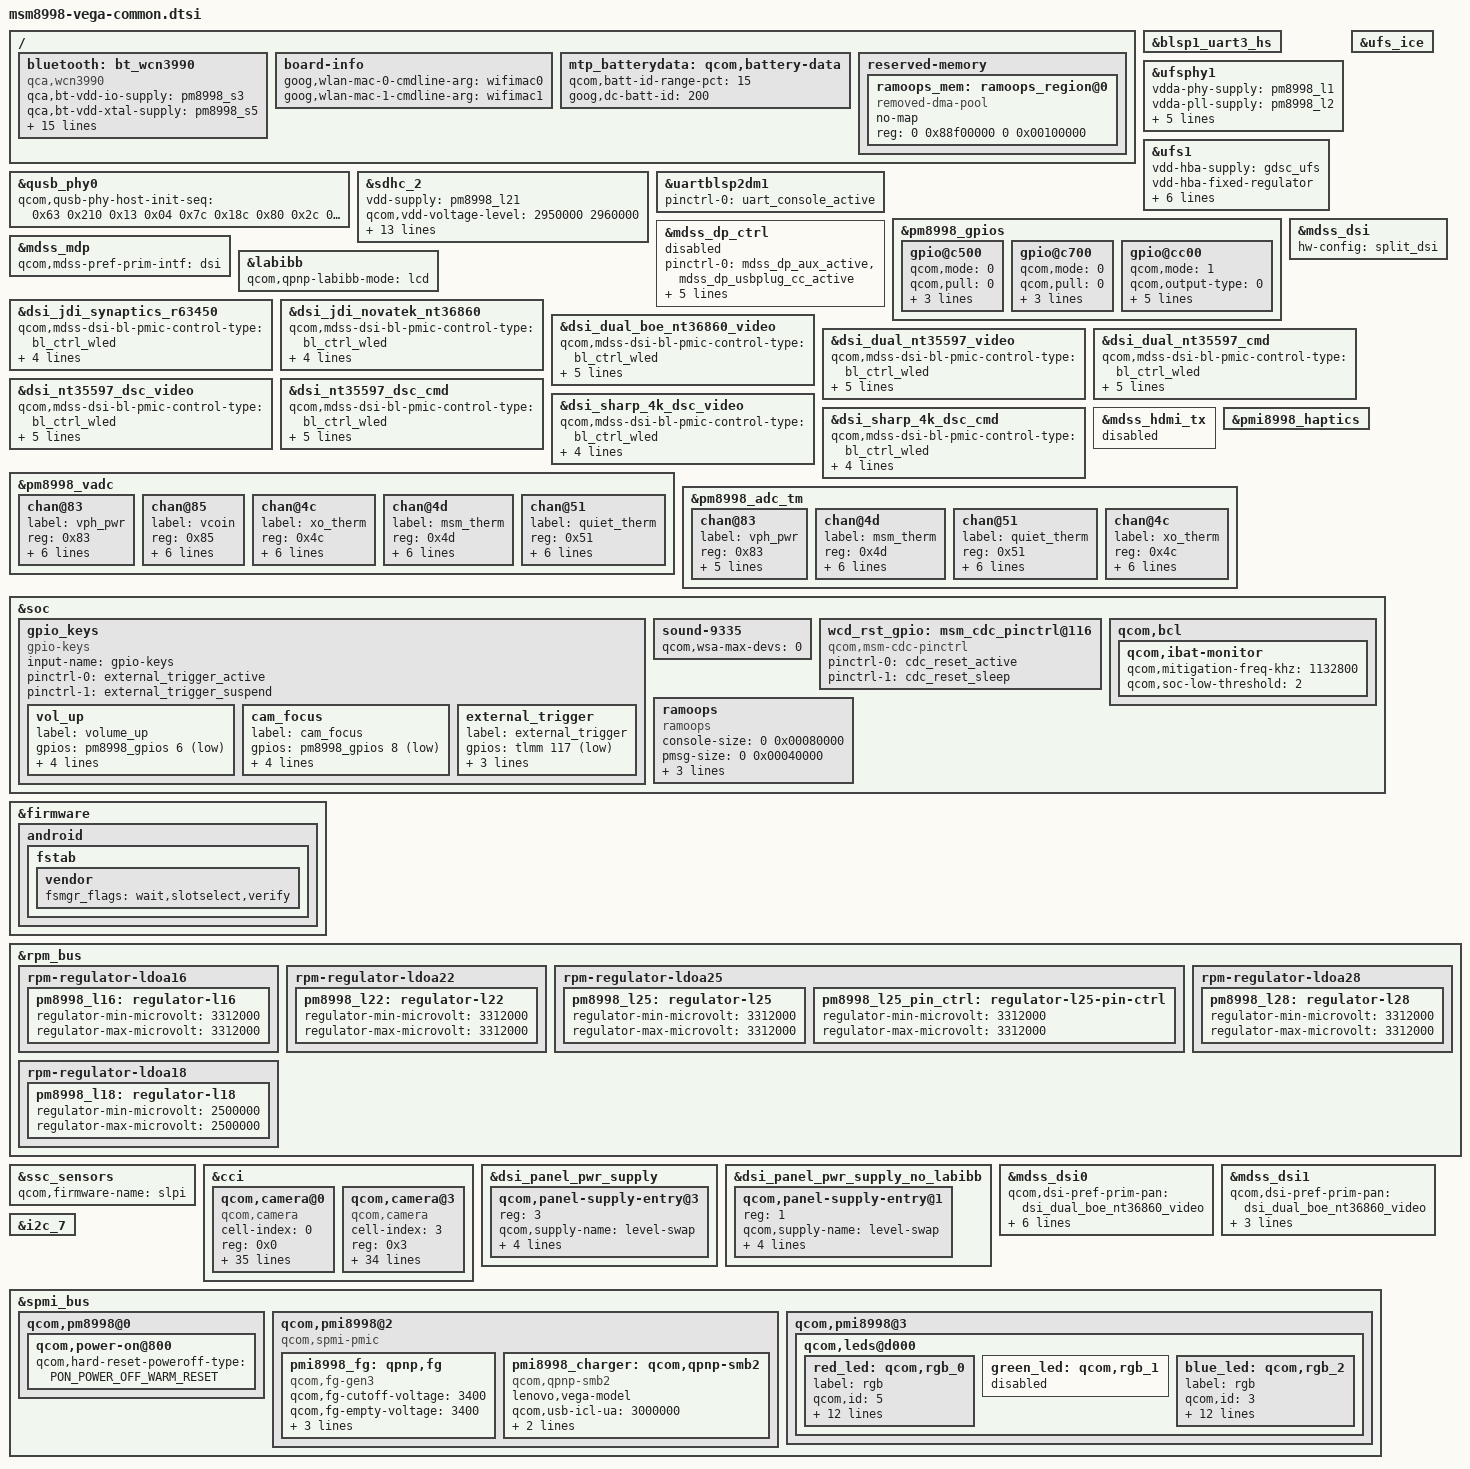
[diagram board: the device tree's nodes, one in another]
/* Copyright (c) 2016, The Linux Foundation. All rights reserved.
 *
 * This program is free software; you can redistribute it and/or modify
 * it under the terms of the GNU General Public License version 2 and
 * only version 2 as published by the Free Software Foundation.
 *
 * This program is distributed in the hope that it will be useful,
 * but WITHOUT ANY WARRANTY; without even the implied warranty of
 * MERCHANTABILITY or FITNESS FOR A PARTICULAR PURPOSE.  See the
 * GNU General Public License for more details.
 */

#include "../qcom/apq8098-v2.1.dtsi"
#include "../qcom/msm8998-camera-sensor-cdp.dtsi"
#include "../qcom/msm8998-mdss-panels.dtsi"

#include <dt-bindings/gpio/gpio.h>
#include <dt-bindings/input/input.h>

#include "../qcom/dsi-panel-jdi-synaptics-r63450.dtsi"
#include "../qcom/dsi-panel-jdi-novatek-nt36860.dtsi"
#include "dsi-panel-boe-nt36860-dualmipi-video.dtsi"
#include "msm8998-vega-pinctrl.dtsi"

/ {
	bluetooth: bt_wcn3990 {
		compatible = "qca,wcn3990";
		qca,bt-vdd-io-supply = <&pm8998_s3>;
		qca,bt-vdd-xtal-supply = <&pm8998_s5>;
		qca,bt-vdd-core-supply = <&pm8998_l7_pin_ctrl>;
		qca,bt-vdd-pa-supply = <&pm8998_l17_pin_ctrl>;
		qca,bt-vdd-ldo-supply = <&pm8998_l25_pin_ctrl>;
		qca,bt-chip-pwd-supply = <&pmi8998_bob_pin1>;

		qca,bt-vdd-io-voltage-level = <1352000 1352000>;
		qca,bt-vdd-xtal-voltage-level = <2040000 2040000>;
		qca,bt-vdd-core-voltage-level = <1800000 1800000>;
		qca,bt-vdd-pa-voltage-level = <1304000 1304000>;
		qca,bt-vdd-ldo-voltage-level = <3312000 3312000>;
		qca,bt-chip-pwd-voltage-level = <3600000 3600000>;

		qca,bt-vdd-io-current-level = <1>; /* LPM/PFM */
		qca,bt-vdd-xtal-current-level = <1>; /* LPM/PFM */
		qca,bt-vdd-core-current-level = <1>; /* LPM/PFM */
		qca,bt-vdd-pa-current-level = <1>; /* LPM/PFM */
		qca,bt-vdd-ldo-current-level = <1>; /* LPM/PFM */
	};

	board-info {
		goog,wlan-mac-0-cmdline-arg = "wifimac0";
		goog,wlan-mac-1-cmdline-arg = "wifimac1";
	};
};

&qusb_phy0 {
	qcom,qusb-phy-host-init-seq =
		/* value reg_offsets> */
		<0x63 0x210
		0x13 0x04
		0x7c 0x18c
		0x80 0x2c
		0x0a 0x184
		0x8c 0x21c
		0x05 0x23c
		0x03 0x240
		0xff 0x218
		0x62 0x210>;
};

&blsp1_uart3_hs {
	status = "ok";
};

&ufsphy1 {
	vdda-phy-supply = <&pm8998_l1>;
	vdda-pll-supply = <&pm8998_l2>;
	vddp-ref-clk-supply = <&pm8998_l26>;
	vdda-phy-max-microamp = <51400>;
	vdda-pll-max-microamp = <14600>;
	vddp-ref-clk-max-microamp = <100>;
	vddp-ref-clk-always-on;
	status = "ok";
};

&ufs1 {
	vdd-hba-supply = <&gdsc_ufs>;
	vdd-hba-fixed-regulator;
	vcc-supply = <&pm8998_l20>;
	vccq-supply = <&pm8998_l26>;
	vccq2-supply = <&pm8998_s4>;
	vcc-max-microamp = <750000>;
	vccq-max-microamp = <560000>;
	vccq2-max-microamp = <750000>;
	status = "ok";
};

&ufs_ice {
	status = "ok";
};

&sdhc_2 {
	vdd-supply = <&pm8998_l21>;
	qcom,vdd-voltage-level = <2950000 2960000>;
	qcom,vdd-current-level = <200 800000>;

	vdd-io-supply = <&pm8998_l13>;
	qcom,vdd-io-voltage-level = <1808000 2960000>;
	qcom,vdd-io-current-level = <200 22000>;

	pinctrl-names = "active", "sleep";
	pinctrl-0 = <&sdc2_clk_on  &sdc2_cmd_on &sdc2_data_on &sdc2_cd_on>;
	pinctrl-1 = <&sdc2_clk_off &sdc2_cmd_off &sdc2_data_off &sdc2_cd_off>;

	qcom,clk-rates = <400000 20000000 25000000
	                        50000000 100000000 200000000>;
	qcom,bus-speed-mode = "SDR12", "SDR25", "SDR50", "DDR50", "SDR104";

	cd-gpios = <&tlmm 95 0x1>;

	status = "ok";
};

&uartblsp2dm1 {
	status = "ok";
	pinctrl-names = "default";
	pinctrl-0 = <&uart_console_active>;
};

&pm8998_gpios {
	/* GPIO 6 for Vol+ Key */
	gpio@c500 {
		status = "okay";
		qcom,mode = <0>;
		qcom,pull = <0>;
		qcom,vin-sel = <0>;
		qcom,src-sel = <0>;
		qcom,out-strength = <1>;
	};

	/* GPIO 8 for Focus Key */
	gpio@c700 {
		status = "okay";
		qcom,mode = <0>;
		qcom,pull = <0>;
		qcom,vin-sel = <0>;
		qcom,src-sel = <0>;
		qcom,out-strength = <1>;
	};

	gpio@cc00 { /* GPIO 13 */
		qcom,mode = <1>;
		qcom,output-type = <0>;
		qcom,pull = <5>;
		qcom,vin-sel = <0>;
		qcom,out-strength = <1>;
		qcom,src-sel = <3>;
		qcom,master-en = <1>;
		status = "okay";
	};
};

&mdss_dp_ctrl {
	status = "disabled";
	pinctrl-names = "mdss_dp_active", "mdss_dp_sleep";
	pinctrl-0 = <&mdss_dp_aux_active &mdss_dp_usbplug_cc_active>;
	pinctrl-1 = <&mdss_dp_aux_suspend &mdss_dp_usbplug_cc_suspend>;
	qcom,aux-en-gpio = <&tlmm 77 0>;
	qcom,aux-sel-gpio = <&tlmm 78 0>;
	qcom,usbplug-cc-gpio = <&tlmm 38 0>;
};

&mdss_mdp {
	qcom,mdss-pref-prim-intf = "dsi";
};

&mdss_dsi {
	hw-config = "split_dsi";
};


&labibb {
	status = "ok";
	qcom,qpnp-labibb-mode = "lcd";
};

&dsi_jdi_synaptics_r63450 {
	qcom,mdss-dsi-bl-pmic-control-type = "bl_ctrl_wled";
	qcom,mdss-dsi-bl-min-level = <1>;
	qcom,mdss-dsi-bl-max-level = <2400>;
	qcom,panel-supply-entries = <&dsi_panel_pwr_supply>;
};

&dsi_jdi_novatek_nt36860 {
	qcom,mdss-dsi-bl-pmic-control-type = "bl_ctrl_wled";
	qcom,mdss-dsi-bl-min-level = <1>;
	qcom,mdss-dsi-bl-max-level = <2400>;
	qcom,panel-supply-entries = <&dsi_panel_pwr_supply>;
};

&dsi_dual_boe_nt36860_video {
	qcom,mdss-dsi-bl-pmic-control-type = "bl_ctrl_wled";
	qcom,mdss-dsi-bl-min-level = <1>;
	qcom,mdss-dsi-bl-max-level = <4095>;
	qcom,mdss-dsi-mode-sel-gpio-state = "dual_port";
	qcom,panel-supply-entries = <&dsi_panel_pwr_supply>;
};

&dsi_dual_nt35597_video {
	qcom,mdss-dsi-bl-pmic-control-type = "bl_ctrl_wled";
	qcom,mdss-dsi-bl-min-level = <1>;
	qcom,mdss-dsi-bl-max-level = <4095>;
	qcom,mdss-dsi-mode-sel-gpio-state = "dual_port";
	qcom,panel-supply-entries = <&dsi_panel_pwr_supply>;
};

&dsi_dual_nt35597_cmd {
	qcom,mdss-dsi-bl-pmic-control-type = "bl_ctrl_wled";
	qcom,mdss-dsi-bl-min-level = <1>;
	qcom,mdss-dsi-bl-max-level = <4095>;
	qcom,mdss-dsi-mode-sel-gpio-state = "dual_port";
	qcom,panel-supply-entries = <&dsi_panel_pwr_supply>;
};

&dsi_nt35597_dsc_video {
	qcom,mdss-dsi-bl-pmic-control-type = "bl_ctrl_wled";
	qcom,mdss-dsi-bl-min-level = <1>;
	qcom,mdss-dsi-bl-max-level = <4095>;
	qcom,mdss-dsi-mode-sel-gpio-state = "single_port";
	qcom,panel-supply-entries = <&dsi_panel_pwr_supply>;
};

&dsi_nt35597_dsc_cmd {
	qcom,mdss-dsi-bl-pmic-control-type = "bl_ctrl_wled";
	qcom,mdss-dsi-bl-min-level = <1>;
	qcom,mdss-dsi-bl-max-level = <4095>;
	qcom,mdss-dsi-mode-sel-gpio-state = "single_port";
	qcom,panel-supply-entries = <&dsi_panel_pwr_supply>;
};

&dsi_sharp_4k_dsc_video {
	qcom,mdss-dsi-bl-pmic-control-type = "bl_ctrl_wled";
	qcom,mdss-dsi-bl-min-level = <1>;
	qcom,mdss-dsi-bl-max-level = <4095>;
	qcom,panel-supply-entries = <&dsi_panel_pwr_supply>;
};

&dsi_sharp_4k_dsc_cmd {
	qcom,mdss-dsi-bl-pmic-control-type = "bl_ctrl_wled";
	qcom,mdss-dsi-bl-min-level = <1>;
	qcom,mdss-dsi-bl-max-level = <4095>;
	qcom,panel-supply-entries = <&dsi_panel_pwr_supply>;
};

&mdss_hdmi_tx {
	status = "disabled";
};

&pmi8998_haptics {
	status = "okay";
};

&pm8998_vadc {
	chan@83 {
		label = "vph_pwr";
		reg = <0x83>;
		qcom,decimation = <2>;
		qcom,pre-div-channel-scaling = <1>;
		qcom,calibration-type = "absolute";
		qcom,scale-function = <0>;
		qcom,hw-settle-time = <0>;
		qcom,fast-avg-setup = <0>;
	};

	chan@85 {
		label = "vcoin";
		reg = <0x85>;
		qcom,decimation = <2>;
		qcom,pre-div-channel-scaling = <1>;
		qcom,calibration-type = "absolute";
		qcom,scale-function = <0>;
		qcom,hw-settle-time = <0>;
		qcom,fast-avg-setup = <0>;
	};

	chan@4c {
		label = "xo_therm";
		reg = <0x4c>;
		qcom,decimation = <2>;
		qcom,pre-div-channel-scaling = <0>;
		qcom,calibration-type = "ratiometric";
		qcom,scale-function = <4>;
		qcom,hw-settle-time = <2>;
		qcom,fast-avg-setup = <0>;
	};

	chan@4d {
		label = "msm_therm";
		reg = <0x4d>;
		qcom,decimation = <2>;
		qcom,pre-div-channel-scaling = <0>;
		qcom,calibration-type = "ratiometric";
		qcom,scale-function = <2>;
		qcom,hw-settle-time = <2>;
		qcom,fast-avg-setup = <0>;
	};

	chan@51 {
		label = "quiet_therm";
		reg = <0x51>;
		qcom,decimation = <2>;
		qcom,pre-div-channel-scaling = <0>;
		qcom,calibration-type = "ratiometric";
		qcom,scale-function = <2>;
		qcom,hw-settle-time = <2>;
		qcom,fast-avg-setup = <0>;
	};
};

&pm8998_adc_tm {
	chan@83 {
		label = "vph_pwr";
		reg = <0x83>;
		qcom,pre-div-channel-scaling = <1>;
		qcom,calibration-type = "absolute";
		qcom,scale-function = <0>;
		qcom,hw-settle-time = <0>;
		qcom,btm-channel-number = <0x60>;
	};

	chan@4d {
		label = "msm_therm";
		reg = <0x4d>;
		qcom,pre-div-channel-scaling = <0>;
		qcom,calibration-type = "ratiometric";
		qcom,scale-function = <2>;
		qcom,hw-settle-time = <2>;
		qcom,btm-channel-number = <0x68>;
		qcom,thermal-node;
	};

	chan@51 {
		label = "quiet_therm";
		reg = <0x51>;
		qcom,pre-div-channel-scaling = <0>;
		qcom,calibration-type = "ratiometric";
		qcom,scale-function = <2>;
		qcom,hw-settle-time = <2>;
		qcom,btm-channel-number = <0x70>;
		qcom,thermal-node;
	};
	chan@4c {
		label = "xo_therm";
		reg = <0x4c>;
		qcom,pre-div-channel-scaling = <0>;
		qcom,calibration-type = "ratiometric";
		qcom,scale-function = <4>;
		qcom,hw-settle-time = <2>;
		qcom,btm-channel-number = <0x78>;
		qcom,thermal-node;
	};
};

&soc {
	/delete-node/ msm_cdc_pinctrl@64;
	gpio_keys {
		compatible = "gpio-keys";
		input-name = "gpio-keys";
		status = "okay";
		pinctrl-names = "tlmm_gpio_key_active", "tlmm_gpio_key_suspend";
		pinctrl-0 = <&external_trigger_active>;
		pinctrl-1 = <&external_trigger_suspend>;

		vol_up {
			label = "volume_up";
			gpios = <&pm8998_gpios 6 0x1>;
			linux,input-type = <1>;
			linux,code = <115>;
			gpio-key,wakeup;
			debounce-interval = <15>;
		};

		cam_focus {
			label = "cam_focus";
			gpios = <&pm8998_gpios 8 0x1>;
			linux,input-type = <1>;
			linux,code = <528>;
			gpio-key,wakeup;
			debounce-interval = <15>;
		};

		external_trigger: external_trigger {
			label = "external_trigger";
			gpios = <&tlmm 117 GPIO_ACTIVE_LOW>;
			linux,input-type = <1>;
			linux,code = <KEY_FN_F5>;
			debounce-interval = <0>;
		};
	};

	sound-9335 {
		/delete-property/qcom,wsa-devs;
		/delete-property/qcom,wsa-aux-dev-prefix;
		qcom,wsa-max-devs = <0>;
	};

	wcd_rst_gpio: msm_cdc_pinctrl@116 {
		compatible = "qcom,msm-cdc-pinctrl";
		pinctrl-names = "aud_active", "aud_sleep";
		pinctrl-0 = <&cdc_reset_active>;
		pinctrl-1 = <&cdc_reset_sleep>;
	};

	qcom,bcl {
		/delete-property/ qcom,bcl-hotplug-list;
		/delete-property/ qcom,bcl-soc-hotplug-list;
		qcom,ibat-monitor {
			qcom,mitigation-freq-khz = <1132800>;
			qcom,soc-low-threshold = <2>;
		};
	};

	ramoops {
		compatible = "ramoops";
		status = "ok";
		console-size = <0 0x00080000>;
		pmsg-size = <0 0x00040000>;
		record-size = <0 0x00008000>;
		ftrace-size = <0 0x00020000>;
		memory-region = <&ramoops_mem>;
	};
};

/{
	mtp_batterydata: qcom,battery-data {
		qcom,batt-id-range-pct = <15>;
		goog,dc-batt-id = <200>;
		#include "2912653_Goertek_Cowboycos_4000mAh_averaged_MasterSlave_Jun12th2017_PMI8998GUI20058.dtsi"
		#include "3066604_Goertek_L17D1P33_4000mAh_averaged_MasterSlave_Aug22nd2017_PMI8998GUI20058.dtsi"
	};
};

&firmware {
	android {
		fstab {
			vendor {
				fsmgr_flags = "wait,slotselect,verify";
			};
		};
	};
};

&pmi8998_charger {
	/delete-property/qcom,batteryless-platform;
};

&rpm_bus {
	rpm-regulator-ldoa16 {
		status = "okay";
		pm8998_l16: regulator-l16 {
			regulator-min-microvolt = <3312000>;
			regulator-max-microvolt = <3312000>;
			status = "okay";
		};
	};

	rpm-regulator-ldoa22 {
		status = "okay";
		pm8998_l22: regulator-l22 {
			regulator-min-microvolt = <3312000>;
			regulator-max-microvolt = <3312000>;
			status = "okay";
		};
	};

	rpm-regulator-ldoa25 {
		pm8998_l25: regulator-l25 {
			regulator-min-microvolt = <3312000>;
			regulator-max-microvolt = <3312000>;
		};

		pm8998_l25_pin_ctrl: regulator-l25-pin-ctrl {
			regulator-min-microvolt = <3312000>;
			regulator-max-microvolt = <3312000>;
		};
	};

	rpm-regulator-ldoa28 {
		status = "okay";
		pm8998_l28: regulator-l28 {
			regulator-min-microvolt = <3312000>;
			regulator-max-microvolt = <3312000>;
			status = "okay";
		};
	};
};

/ {
	reserved-memory {
		ramoops_mem: ramoops_region@0 {
			compatible = "removed-dma-pool";
			no-map;
			reg = <0 0x88f00000 0 0x00100000>;
		};
	};
};

&ssc_sensors {
	/* SLPI firmware files are spli.* */
	qcom,firmware-name = "slpi";
};

&cci {
	qcom,camera@0 {
		cell-index = <0>;
		compatible = "qcom,camera";
		reg = <0x0>;
		qcom,csiphy-sd-index = <0>;
		qcom,csid-sd-index = <0>;
		qcom,mount-angle = <270>;
		cam_v_custom1-supply = <&pm8998_lvs1>;
		cam_vio-supply = <&pm8998_l9>;
		cam_vana-supply = <&pm8998_l22>;
		cam_vdig-supply = <&pm8998_l8>;
		qcom,cam-vreg-name = "cam_v_custom1", "cam_vio", "cam_vana", "cam_vdig";
		qcom,cam-custom-vreg-name = "cam_v_custom1";
		qcom,cam-vreg-type = <1 0 0 0>;
		qcom,cam-vreg-min-voltage = <0 1808000 3312000 1200000>;
		qcom,cam-vreg-max-voltage = <0 2960000 3312000 1200000>;
		qcom,cam-vreg-op-mode = <0 105000 80000 105000>;
		qcom,gpio-no-mux = <0>;
		pinctrl-names = "cam_default", "cam_suspend";
		pinctrl-0 = <&cam_sensor_mclk0_active
				&cam_sensor_6dofl_active>;
		pinctrl-1 = <&cam_sensor_mclk0_suspend
				 &cam_sensor_6dofl_suspend>;
		gpios = <&tlmm 13 0>,
			<&tlmm 148 0>,
			<&tlmm 52 0>,
			<&tlmm 93 0>;
		qcom,gpio-reset = <1>;
		qcom,gpio-vana = <2>;
		qcom,gpio-vio  = <3>;
		qcom,gpio-req-tbl-num = <0 1 2 3>;
		qcom,gpio-req-tbl-flags = <1 0 0 0>;
		qcom,gpio-req-tbl-label = "CAMIF_MCLK",
		        "CAM_RESET",
		        "CAM_VANA",
		        "CAM_VDIG";
		qcom,sensor-position = <0>;
		qcom,sensor-mode = <1>;
		qcom,cci-master = <0>;
		status = "ok";
		clocks = <&clock_mmss clk_mclk0_clk_src>,
		        <&clock_mmss clk_mmss_camss_mclk0_clk>;
		clock-names = "cam_src_clk", "cam_clk";
		qcom,clock-rates = <24000000 0>;
	};
	qcom,camera@3 {
		cell-index = <3>;
		compatible = "qcom,camera";
		reg = <0x3>;
		qcom,csiphy-sd-index = <0>;
		qcom,csid-sd-index = <0>;
		qcom,mount-angle = <270>;
		cam_v_custom1-supply = <&pm8998_lvs1>;
		cam_vdig-supply = <&pm8998_l8>;
		cam_vio-supply = <&pm8998_l9>;
		cam_vana-supply = <&pm8998_l22>;
		qcom,cam-vreg-name = "cam_v_custom1", "cam_vdig", "cam_vio", "cam_vana";
		qcom,cam-vreg-type = <1 0 0 0>;
		qcom,cam-custom-vreg-name = "cam_v_custom1";
		qcom,cam-vreg-min-voltage = <1700000 1140000 1700000 3312000>;
		qcom,cam-vreg-max-voltage = <3000000 1260000 3000000 3312000>;
		qcom,cam-vreg-op-mode = <1800000 1200000 1800000 2800000>;
		qcom,gpio-no-mux = <0>;
		pinctrl-names = "cam_default", "cam_suspend";
		pinctrl-0 = <&cam_sensor_6dofr_active>;
		pinctrl-1 = <&cam_sensor_6dofr_suspend>;
		gpios = <&tlmm 13 0>,
			<&tlmm 149 0>,
			<&tlmm 52 0>,
			<&tlmm 93 0>;
		qcom,gpio-reset = <1>;
		qcom,gpio-vana  = <2>;
		qcom,gpio-vio   = <3>;
		qcom,gpio-req-tbl-num = <0 1 2 3>;
		qcom,gpio-req-tbl-flags = <1 0 0 0>;
		qcom,gpio-req-tbl-label = "CAMIF_MCLK",
			"CAM_RESET",
			"CAM_VANA",
			"CAM_VDIG";
		qcom,sensor-position = <1>;
		qcom,sensor-mode = <1>;
		qcom,cci-master = <0>;
		status = "ok";
		clocks = <&clock_mmss clk_mclk0_clk_src>,
			<&clock_mmss clk_mmss_camss_mclk0_clk>;
		clock-names = "cam_src_clk", "cam_clk";
		qcom,clock-rates = <24000000 0>;
	};
};

&rpm_bus {
	rpm-regulator-ldoa18 {
		status = "okay";
		pm8998_l18: regulator-l18 {
			regulator-min-microvolt = <2500000>;
			regulator-max-microvolt = <2500000>;
			status = "okay";
		};
	};
};

&dsi_panel_pwr_supply {
	qcom,panel-supply-entry@3 {
		reg = <3>;
		qcom,supply-name = "level-swap";
		qcom,supply-min-voltage = <3008000>;
		qcom,supply-max-voltage = <3008000>;
		qcom,supply-enable-load = <100000>;
		qcom,supply-disable-load = <100>;
	};
};

&dsi_panel_pwr_supply_no_labibb{
	qcom,panel-supply-entry@1 {
		reg = <1>;
		qcom,supply-name = "level-swap";
		qcom,supply-min-voltage = <3008000>;
		qcom,supply-max-voltage = <3008000>;
		qcom,supply-enable-load = <100000>;
		qcom,supply-disable-load = <100>;
	};
};

&mdss_dsi0 {
	qcom,dsi-pref-prim-pan = <&dsi_dual_boe_nt36860_video>;
	pinctrl-names = "mdss_default", "mdss_sleep";
	pinctrl-0 = <&mdss_dsi_active &mdss_te_active>;
	pinctrl-1 = <&mdss_dsi_suspend &mdss_te_suspend>;
	qcom,platform-bklight-en-gpio = <&tlmm 39 0>;
	qcom,platform-reset-gpio = <&tlmm 94 0>;
	qcom,platform-te-gpio = <&tlmm 96 0>;
	level-swap-supply = <&pm8998_l19>;
};

&mdss_dsi1 {
	qcom,dsi-pref-prim-pan = <&dsi_dual_boe_nt36860_video>;
	qcom,platform-bklight-en-gpio = <&tlmm 39 0>;
	qcom,platform-te-gpio = <&tlmm 96 0>;
	level-swap-supply = <&pm8998_l19>;
};

&i2c_7 {
	/delete-node/qcom,smb138x@8;
};
&spmi_bus {
	qcom,pm8998@0 {
		qcom,power-on@800 {
			qcom,hard-reset-poweroff-type = <PON_POWER_OFF_WARM_RESET>;
		};
	};
	qcom,pmi8998@2 {
		compatible = "qcom,spmi-pmic";
		pmi8998_fg: qpnp,fg {
			compatible = "qcom,fg-gen3";
			qcom,fg-cutoff-voltage = <3400>;
			qcom,fg-empty-voltage = <3400>;
			qcom,fg-chg-term-current = <200>;
			qcom,fg-jeita-thresholds = <0 15 43 50>;
			qcom,fg-rsense-sel = <0>; /* SRC_SEL_BATFET */
		};

		pmi8998_charger: qcom,qpnp-smb2 {
			compatible = "qcom,qpnp-smb2";
			lenovo,vega-model;
			qcom,usb-icl-ua = <3000000>;
			qcom,otg-cl-ua = <800000>;
			qcom,max-9v-adapter;
		};
	};
	qcom,pmi8998@3 {
		qcom,leds@d000 {
			red_led: qcom,rgb_0 {
				/delete-property/ linux,default-trigger;
				label = "rgb";
				qcom,id = <5>;
				qcom,mode = "pwm";
				pwms = <&pmi8998_pwm_3 0 0>;
				qcom,pwm-us = <100>;
				qcom,max-current = <12>;
				qcom,default-state = "off";
				linux,name = "red";

				qcom,use-blink;
				qcom,start-idx = <1>;
				qcom,idx-len = <18>;
				qcom,duty-pcts = [00 10 00 10 00 10 00 00 00 00 00 00 00 00 00 00 00 00];
				qcom,ramp-step-ms = <83>;
			};

			green_led: qcom,rgb_1 {
				/delete-property/ linux,default-trigger;
				status = "disabled";
			};

			blue_led: qcom,rgb_2 {
				/delete-property/ linux,default-trigger;
				label = "rgb";
				qcom,id = <3>;
				qcom,mode = "pwm";
				pwms = <&pmi8998_pwm_5 0 0>;
				qcom,pwm-us = <100>;
				qcom,max-current = <12>;
				qcom,default-state = "keep";
				linux,name = "blue";

				qcom,use-blink;
				qcom,start-idx = <1>;
				qcom,idx-len = <40>;
				qcom,duty-pcts = [ 09 0B 0C 0E 0F 10 11 12
						   12 13 13 13 12 12 11 10
						   0F 0E 0C 0B 09 08 07 05
						   04 03 02 01 00 00 00 00
						   00 01 02 03 04 05 07 08 ];
				qcom,ramp-step-ms = <25>;
			};
		};
	};
};
